# MM32F3270 register map
File version: 3.01
CPU: CM3 r2p1, selectable endian, MPU, no FPU, 3 interrupt priority bits
Registers are 32-bit, read-write, reset 0x0 unless marked. A register's access mark holds for its fields unless they carry their own. Offsets are from the block's base; [hi:lo] are bit positions; {n}, {i} and the like mark numbered series.

## OTG_FS — USB On-The-Go Full-Speed
Base 0x50000000
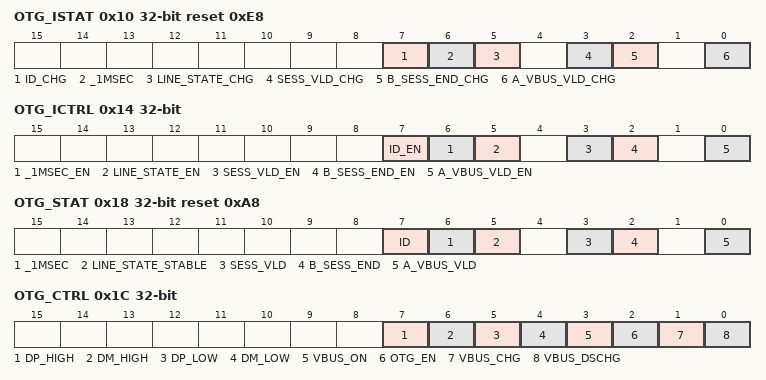
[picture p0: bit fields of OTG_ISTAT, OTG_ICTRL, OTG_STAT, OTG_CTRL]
0x10 OTG_ISTAT reset 0xE8 write-1-clears — OTG Interrupt Status Register
  [7] ID_CHG — When the USB ID pin signal is detected to be changed, the position bit.
  [6] _1MSEC — This bit is set when the 1 ms timer expires.
  [5] LINE_STATE_CHG — The interrupt can be used to detect reset and recover.
  [3] SESS_VLD_CHG — When a VBUS change is detected, the position bit indicates that the session is valid or the session is no longer valid.
  [2] B_SESS_END_CHG — This position bit when a VBUS change is detected on the B device.
  [0] A_VBUS_VLD_CHG — This position is 1 when a VBUS change is detected on the A device.
0x14 OTG_ICTRL — OTG Interrupt Control Register
  [7] ID_EN — Enable ID signal interrupt
  [6] _1MSEC_EN — Enable 1 ms timer interrupt.
  [5] LINE_STATE_EN — Enable line state change interrupt.
  [3] SESS_VLD_EN — Enables the session to be effectively interrupted
  [2] B_SESS_END_EN — Enable b device VBUS valid interrupt
  [0] A_VBUS_VLD_EN — Enable a device VBUS valid interrupt
0x18 OTG_STAT reset 0xA8 — OTG Status Register
  [7] ID — Indicates the current status of the ID pin on the USB connector
  [6] _1MSEC — This bit is reserved for the 1 ms counter and is not valid for software
  [5] LINE_STATE_STABLE — Dithering
  [3] SESS_VLD — This bit is set when the VBUS voltage is higher than the valid threshold of the B device session bit
  [2] B_SESS_END — This bit is set when the VBUS voltage is below the B device session end threshold
  [0] A_VBUS_VLD — When the VBUS voltage is higher than the VBUS effective threshold of a device, this bit will be set bit
0x1C OTG_CTRL — OTG Control register
  [7] DP_HIGH — When set, a pull_up resistor is enabled on the d_plus_data line
  [6] DM_HIGH — When set, a pull_up resistor is enabled on the d_reduce_data line
  [5] DP_LOW — When set, a pull_down resistor is enabled on the d_plus_data line
  [4] DM_LOW — When set, a pull_down resistor is enabled on the d_reduce_data line
  [3] VBUS_ON — When set, the VBUS power signal will be turned on
  [2] OTG_EN — When set, the pull_up and pull_down controls in this register can be used
  [1] VBUS_CHG — When set, this will release the VBUS signal through the resistance. When set, it will send the VBUS signal through the resistance
  [0] VBUS_DSCHG — When set, this releases the VBUS signal through the resistance
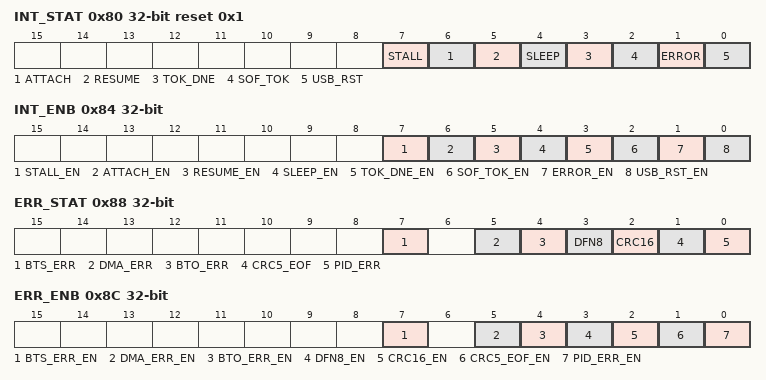
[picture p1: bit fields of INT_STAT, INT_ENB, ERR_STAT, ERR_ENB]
0x80 INT_STAT reset 0x1 — Interrupt status register
  [7] STALL — Stall interrupt is used in slave mode and master mode. In slave mode,SIE set when sending stall handshake packet.
  [6] ATTACH — If OTG_FS detects a connection to a USB peripheral, the location bit
  [5] RESUME — When the K state is observed on the DP_DM signal line within 2.5 microseconds, this position 1
  [4] SLEEP — If otg_fs detects 3MS idle on the USB bus signal, then Position 1
  [3] TOK_DNE — This bit is set when the token being processed completes
  [2] SOF_TOK — If the otg_fs receives a sof token, this location bit
  [1] ERROR — This position bit when any error condition in the ERR_STAT register occurs
  [0] USB_RST — When otg_fs decodes valid USB reset, this position bit
0x84 INT_ENB — Interrupt enable register
  [7] STALL_EN — This position bit will enable STALL interrupt.
  [6] ATTACH_EN — This position bit will enable ATTACH interrupt
  [5] RESUME_EN — This position bit will enable RESUME interrupt
  [4] SLEEP_EN — This position bit will enable SLEEP interrupt
  [3] TOK_DNE_EN — This position bit will enable SOF_ Tok interrupt
  [2] SOF_TOK_EN — This position bit will enable TOK_END interrupt
  [1] ERROR_EN — Setting this bit enables the ERROR interrupt
  [0] USB_RST_EN — Setting this bit will enable USB_ RST interrupt
0x88 ERR_STAT — Error interrupt status register
  [7] BTS_ERR — Bit stuff is set when the error is detected. The corresponding packet will be rejected
  [5] DMA_ERR — If DMA error,this position 1
  [4] BTO_ERR — If a bus turnaround timeout error occurs, the location bit
  [3] DFN8 — The received data field is not 8 bits
  [2] CRC16 — CRC16 failed
  [1] CRC5_EOF — This error interrupt has two functions
  [0] PID_ERR — PID check field failed
0x8C ERR_ENB — Error interrupt enable register
  [7] BTS_ERR_EN — Setting this bit enables BTS_ERR interrupt.
  [5] DMA_ERR_EN — Setting this bit enables DMA_ERR interrupt.
  [4] BTO_ERR_EN — Setting this bit enables BTO_ERR interrupt.
  [3] DFN8_EN — Setting this bit enables DFN8 interrupt.
  [2] CRC16_EN — Setting this bit enables CRC16 interrupt.
  [1] CRC5_EOF_EN — Setting this bit enables CRC5orEOF interrupt.
  [0] PID_ERR_EN — Setting this bit enables PID_ Err interrupt
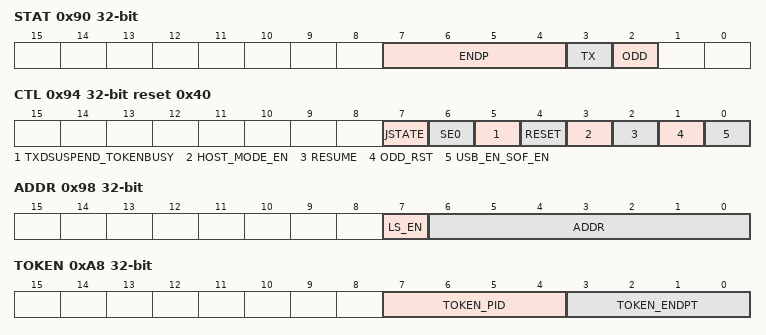
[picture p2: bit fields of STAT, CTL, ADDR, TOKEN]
0x90 STAT ro — Status register
  [7:4] ENDP — These four bits encode the address of the endpoint that received or sent the previous token.
  [3] TX — This bit indicates that the last updated BDT was used for transmit transmission OR receive data transmission
  [2] ODD — This bit indicates that the last buffer descriptor updated is in the odd set of BDT
0x94 CTL reset 0x40 — Control register
  [7] JSTATE — USB differential receiver receives jstate signal
  [6] SE0 — SE0 signal received by USB differential receiver
  [5] TXDSUSPEND_TOKENBUSY — When otg_fs is in slave mode,it is TXD_ Suspend token when otg_fs is in host mode_ Busy
  [4] RESET — Setting this bit will cause otg_fs to generate USB reset signal
  [3] HOST_MODE_EN — Setting this bit causes the otg_fs to work in host mode
  [2] RESUME — Setting this bit will allow the otg_fs to perform the recovery signal
  [1] ODD_RST — Setting this bit will reset all BDT odd Ping_Pong bits to 0 and then specify an even number of BDT libraries
  [0] USB_EN_SOF_EN — Setting this bit will make otg_fs work, clearing it will disable otg_fs
0x98 ADDR — Address register
  [7] LS_EN — Enabling this bit tells otg_fs that the next token command to write to the token register must be executed at a low speed.
  [6:0] ADDR — The USB address of the host is defined in the usb_7 mode
0x9C BDT_PAGE_01 — BDT page register 1
  [7:1] BDT_BA — The 7_bit value provides address bits 15 to 9 of the BDT base address,which defines the location of the buffer descriptor table in the system memory
0xA0 FRM_NUML ro — Frame number register
  [7:0] FRM_7_0 — These bits represent the lower 8 bits of 11 bit frames
0xA4 FRM_NUMH ro — Frame number register
  [2:0] FRM_10_8 — These bits represent the higher 8 bits of 11 bit frames
0xA8 TOKEN
  [7:4] TOKEN_PID — This 4_bit value is the token type executed by Vsub
  [3:0] TOKEN_ENDPT — This 4_bit value determines the endpoint address of the token command
0xAC SOF_THLD — SOF threshold register
  [7:0] CNT — These bits represent the sof count threshold for byte time
0xB0 BDT_PAGE_02 — BDT page register 2
  [7:0] BDT_BA_23_16 — The 8_bit value provides address bits 23 to 16 of the BDT base address, which defines the location of the buffer descriptor table in the system memory
0xB4 BDT_PAGE_03 — BDT page register 3
  [7:0] BDT_BA_31_24 — The 8_bit value provides address bits 31 to 24 of the BDT base address, which defines the location of the buffer descriptor table in the system memory
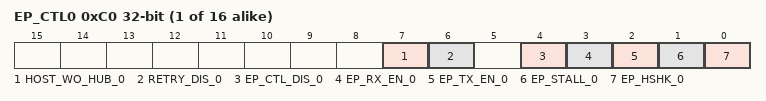
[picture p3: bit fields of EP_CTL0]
{0xC0+4i} EP_CTL{i} (i=0..15) — Endpoint control register
  [7] HOST_WO_HUB_{i} — This is a bit for master mode only and exists only in the control endpt0_rg register of endpoint 0.
  [6] RETRY_DIS_{i} — This is a bit for master mode only and exists only in the control register of endpoint 0
  [4] EP_CTL_DIS_{i} — These three bits define whether the endpoint is enabled and the direction of the endpoint
  [3] EP_RX_EN_{i} — These three bits define whether the endpoint is enabled and the direction of the endpoint
  [2] EP_TX_EN_{i} — These three bits define whether the endpoint is enabled and the direction of the endpoint
  [1] EP_STALL_{i} — Any access to this endpoint will cause the otg_fs to return a stall handshake
  [0] EP_HSHK_{i} — Setting this bit defines whether the endpoint performs a handshake to the endpoint during the transaction
